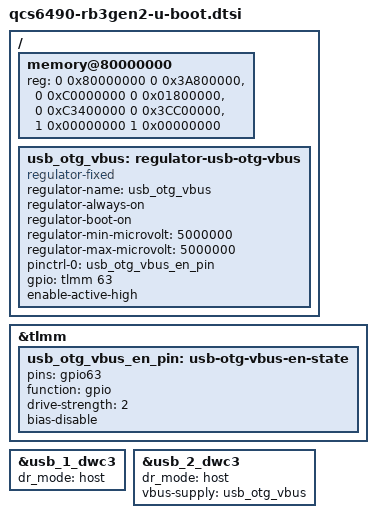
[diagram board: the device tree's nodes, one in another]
// SPDX-License-Identifier: BSD-3-Clause
/*
 * Copyright (c) 2024 Linaro Ltd.
 */
/ {
	/* When running as the primary bootloader there is no prior
	 * stage to populate the memory layout for us. We *should*
	 * have two nodes here, but ABL does NOT like that.
	 * sooo we're stuck with this.
	 */
	memory@80000000 {
		device_type = "memory";
		reg = <0 0x80000000 0 0x3A800000>,
		      <0 0xC0000000 0 0x01800000>,
		      <0 0xC3400000 0 0x3CC00000>,
		      <1 0x00000000 1 0x00000000>;
	};

	usb_otg_vbus: regulator-usb-otg-vbus {
		compatible = "regulator-fixed";
		regulator-name = "usb_otg_vbus";
		regulator-always-on;
		regulator-boot-on;
		regulator-min-microvolt = <5000000>;
		regulator-max-microvolt = <5000000>;
		pinctrl-0 = <&usb_otg_vbus_en_pin>;
		pinctrl-names = "default";
		gpio = <&tlmm 63 GPIO_ACTIVE_HIGH>;
		enable-active-high;
	};
};

&tlmm {
	usb_otg_vbus_en_pin: usb-otg-vbus-en-state {
		pins = "gpio63";
		function = "gpio";
		drive-strength = <2>;
		bias-disable;
	};
};

&usb_1_dwc3 {
	dr_mode = "host";
	/delete-property/ usb-role-switch;
};

&usb_2_dwc3 {
	dr_mode = "host";
	/delete-property/ usb-role-switch;

	vbus-supply = <&usb_otg_vbus>;
};

// RAM Entry 0 : Base 0x0080000000  Size 0x003A800000
// RAM Entry 1 : Base 0x00C0000000  Size 0x0001800000
// RAM Entry 2 : Base 0x00C3400000  Size 0x003CC00000
// RAM Entry 3 : Base 0x0100000000  Size 0x0100000000
